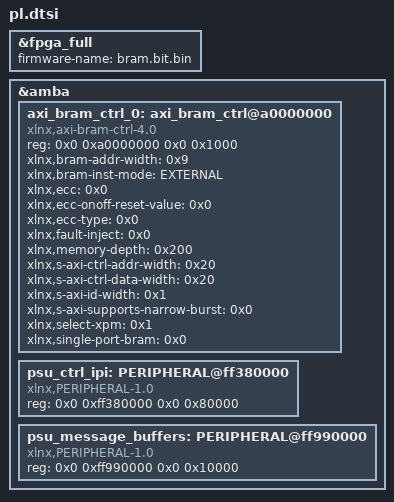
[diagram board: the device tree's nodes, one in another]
/*
 * CAUTION: This file is automatically generated by Xilinx.
 * Version:  
 * Today is: Mon Aug 27 15:28:57 2018
 */


/dts-v1/;
/plugin/;
/ {
	fragment@0 {
		target = <&fpga_full>;
		overlay0: __overlay__ {
			#address-cells = <2>;
			#size-cells = <2>;
			firmware-name = "bram.bit.bin";
		};
	};
	fragment@1 {
		target = <&amba>;
		overlay1: __overlay__ {
			axi_bram_ctrl_0: axi_bram_ctrl@a0000000 {
				compatible = "xlnx,axi-bram-ctrl-4.0";
				reg = <0x0 0xa0000000 0x0 0x1000>;
				xlnx,bram-addr-width = <0x9>;
				xlnx,bram-inst-mode = "EXTERNAL";
				xlnx,ecc = <0x0>;
				xlnx,ecc-onoff-reset-value = <0x0>;
				xlnx,ecc-type = <0x0>;
				xlnx,fault-inject = <0x0>;
				xlnx,memory-depth = <0x200>;
				xlnx,s-axi-ctrl-addr-width = <0x20>;
				xlnx,s-axi-ctrl-data-width = <0x20>;
				xlnx,s-axi-id-width = <0x1>;
				xlnx,s-axi-supports-narrow-burst = <0x0>;
				xlnx,select-xpm = <0x1>;
				xlnx,single-port-bram = <0x0>;
			};
			psu_ctrl_ipi: PERIPHERAL@ff380000 {
				compatible = "xlnx,PERIPHERAL-1.0";
				reg = <0x0 0xff380000 0x0 0x80000>;
			};
			psu_message_buffers: PERIPHERAL@ff990000 {
				compatible = "xlnx,PERIPHERAL-1.0";
				reg = <0x0 0xff990000 0x0 0x10000>;
			};
		};
	};
};
